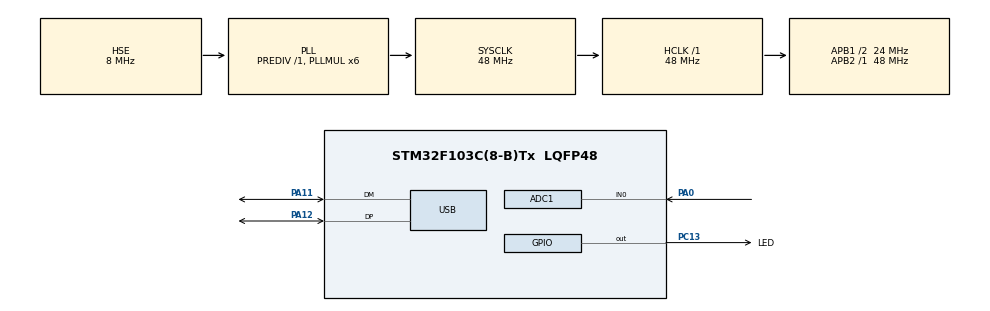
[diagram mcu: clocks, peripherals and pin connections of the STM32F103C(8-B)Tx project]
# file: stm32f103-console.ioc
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ADC1.Channel-0\#ChannelRegularConversion=ADC_CHANNEL_0
ADC1.ExternalTrigConv=ADC_SOFTWARE_START
ADC1.NbrOfConversionFlag=1
ADC1.Rank-0\#ChannelRegularConversion=1
ADC1.SamplingTime-0\#ChannelRegularConversion=ADC_SAMPLETIME_1CYCLE_5
ADC1.master=1
Dma.ADC1.0.Direction=DMA_PERIPH_TO_MEMORY
Dma.ADC1.0.Instance=DMA1_Channel1
Dma.ADC1.0.MemDataAlignment=DMA_MDATAALIGN_HALFWORD
Dma.ADC1.0.MemInc=DMA_MINC_ENABLE
Dma.ADC1.0.Mode=DMA_CIRCULAR
Dma.ADC1.0.PeriphDataAlignment=DMA_PDATAALIGN_HALFWORD
Dma.ADC1.0.PeriphInc=DMA_PINC_DISABLE
Dma.ADC1.0.Priority=DMA_PRIORITY_LOW
Dma.Request0=ADC1
FREERTOS.Tasks01=defaultTask,24,128,StartDefaultTask,Default,NULL,Dynamic,NULL,NULL
Mcu.Family=STM32F1
Mcu.Name=STM32F103C(8-B)Tx
Mcu.Package=LQFP48
NVIC.DMA1_Channel1_IRQn=true\:5\:0\:false\:false\:true\:true\:false\:true\:true
NVIC.PriorityGroup=NVIC_PRIORITYGROUP_4
NVIC.USB_LP_CAN1_RX0_IRQn=true\:5\:0\:false\:false\:true\:true\:false\:true\:true
PA0-WKUP.Signal=ADCx_IN0
PA11.Mode=Device
PA11.Signal=USB_DM
PA12.Mode=Device
PA12.Signal=USB_DP
PC13-TAMPER-RTC.GPIO_Label=LED
PC13-TAMPER-RTC.Signal=GPIO_Output
PD0-OSC_IN.Mode=HSE-External-Oscillator
PD0-OSC_IN.Signal=RCC_OSC_IN
PD1-OSC_OUT.Mode=HSE-External-Oscillator
PD1-OSC_OUT.Signal=RCC_OSC_OUT
ProjectManager.HeapSize=0x200
ProjectManager.StackSize=0x400
ProjectManager.TargetToolchain=STM32CubeIDE
RCC.ADCPresc=RCC_ADCPCLK2_DIV4
RCC.AHBFreq_Value=48000000
RCC.APB1CLKDivider=RCC_HCLK_DIV2
RCC.APB1Freq_Value=24000000
RCC.APB1TimFreq_Value=48000000
RCC.APB2Freq_Value=48000000
RCC.APB2TimFreq_Value=48000000
RCC.HCLKFreq_Value=48000000
RCC.PLLMUL=RCC_PLL_MUL6
RCC.SYSCLKFreq_VALUE=48000000
RCC.SYSCLKSource=RCC_SYSCLKSOURCE_PLLCLK
RCC.USBFreq_Value=48000000
SH.ADCx_IN0.0=ADC1_IN0,IN0
USB_DEVICE.CLASS_NAME_FS=CDC
USB_DEVICE.VirtualMode=Cdc
USB_DEVICE.VirtualModeFS=Cdc_FS
VP_FREERTOS_VS_CMSIS_V2.Mode=CMSIS_V2
VP_SYS_VS_ND.Mode=No_Debug
VP_TIM3_VS_ClockSourceINT.Mode=Internal
VP_USB_DEVICE_VS_USB_DEVICE_CDC_FS.Mode=CDC_FS
board=custom

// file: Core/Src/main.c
/* USER CODE BEGIN Header */
/**
  ******************************************************************************
  * @file           : main.c
  * @brief          : Main program body
  ******************************************************************************
  * @attention
  *
  * Copyright (c) 2025 STMicroelectronics.
  * All rights reserved.
  *
  * This software is licensed under terms that can be found in the LICENSE file
  * in the root directory of this software component.
  * If no LICENSE file comes with this software, it is provided AS-IS.
  *
  ******************************************************************************
  */
/* USER CODE END Header */
#include "main.h"
#include "cmsis_os.h"
#include "usb_device.h"
#include "shell.h"
#include "FreeRTOS.h"
#include "task.h"

ADC_HandleTypeDef hadc1;
DMA_HandleTypeDef hdma_adc1;

TIM_HandleTypeDef htim3;

volatile uint32_t g_boot_stage = 0U;
volatile uint32_t g_usb_stage = 0U;

/* Definitions for defaultTask */
osThreadId_t defaultTaskHandle;
static StaticTask_t defaultTaskControlBlock;
static StackType_t defaultTaskStack[128];
const osThreadAttr_t defaultTask_attributes = {
  .name = "defaultTask",
  .cb_mem = &defaultTaskControlBlock,
  .cb_size = sizeof(defaultTaskControlBlock),
  .stack_mem = defaultTaskStack,
  .stack_size = sizeof(defaultTaskStack),
  .priority = (osPriority_t) osPriorityNormal,
};

/* Shell task */
osThreadId_t shellTaskHandle;
static StaticTask_t shellTaskControlBlock;
static StackType_t shellTaskStack[256];
const osThreadAttr_t shellTask_attributes = {
  .name = "shellTask",
  .cb_mem = &shellTaskControlBlock,
  .cb_size = sizeof(shellTaskControlBlock),
  .stack_mem = shellTaskStack,
  .stack_size = sizeof(shellTaskStack),
  .priority = (osPriority_t) osPriorityNormal,
};

void SystemClock_Config(void);
static HAL_StatusTypeDef SystemClock_Config_HSI_Fallback(void);
static void LED_Output_Init(void);
static volatile LedMode led_mode = LED_MODE_BLINK;
static void MX_GPIO_Init(void);
static void MX_DMA_Init(void);
static void MX_ADC1_Init(void);
static void MX_TIM3_Init(void);
void StartDefaultTask(void *argument);

int main(void)
{

  /* MCU Configuration--------------------------------------------------------*/

  g_boot_stage = 1U;

  /* Reset of all peripherals, Initializes the Flash interface and the Systick. */
  HAL_Init();
  g_boot_stage = 2U;

  /* Make startup failures visible even if the external HSE is unavailable. */
  LED_Output_Init();

#ifndef STM32_DIAG_RTOS_ONLY
  /* Configure the system clock */
  SystemClock_Config();
  g_boot_stage = 3U;
#else
  /* Keep the diagnostic on the reset HSI clock.  This isolates the RTOS and
     GPIO path from HSE/PLL and all application peripherals. */
  g_boot_stage = 3U;
#endif

  /* Initialize all configured peripherals */
#ifndef STM32_DIAG_RTOS_ONLY
  MX_GPIO_Init();
  MX_DMA_Init();
  MX_ADC1_Init();
  MX_TIM3_Init();
#endif
  /* USER CODE BEGIN 2 */
#if !defined(STM32_DIAG_NO_USB) && !defined(STM32_DIAG_RTOS_ONLY)
  Shell_Init();
#endif
  /* PC13 is the physical Blue Pill LED.  Keep it owned by the heartbeat and
     prevent a persisted shell setting from leaving it as an input. */
  LED_Output_Init();
  /* Re-apply the persisted LED mode after the GPIO initialization default. */
  LED_SetMode(LED_GetMode());
  g_boot_stage = 4U;

  /* USER CODE END 2 */

  /* Init scheduler */
  osKernelInitialize();

  /* Create the thread(s) */
  /* creation of defaultTask */
  defaultTaskHandle = osThreadNew(StartDefaultTask, NULL, &defaultTask_attributes);

  shellTaskHandle = NULL;
#if !defined(STM32_DIAG_NO_USB) && !defined(STM32_DIAG_RTOS_ONLY)
  shellTaskHandle = osThreadNew(Shell_Task, NULL, &shellTask_attributes);
#endif
  if (defaultTaskHandle == NULL
#if !defined(STM32_DIAG_NO_USB) && !defined(STM32_DIAG_RTOS_ONLY)
      || shellTaskHandle == NULL
#endif
     )
  {
    Error_Handler();
  }
  g_boot_stage = 5U;

  /* Start scheduler */
  g_boot_stage = 6U;
  osKernelStart();

  /* We should never get here as control is now taken by the scheduler */

  /* Infinite loop */
  while (1)
  {

  }
}

void SystemClock_Config(void)
{
  RCC_OscInitTypeDef osc = {0};
  RCC_ClkInitTypeDef clk = {0};
  RCC_PeriphCLKInitTypeDef periph = {0};

  /* Blue Pill USB needs a stable external 8 MHz reference. */
  osc.OscillatorType = RCC_OSCILLATORTYPE_HSE;
  osc.HSEState = RCC_HSE_ON;
  osc.HSEPredivValue = RCC_HSE_PREDIV_DIV1;
  osc.HSIState = RCC_HSI_ON;
  osc.PLL.PLLState = RCC_PLL_ON;
  osc.PLL.PLLSource = RCC_PLLSOURCE_HSE;
  osc.PLL.PLLMUL = RCC_PLL_MUL6;

  if (HAL_RCC_OscConfig(&osc) == HAL_OK)
  {
    clk.ClockType = RCC_CLOCKTYPE_HCLK | RCC_CLOCKTYPE_SYSCLK |
                    RCC_CLOCKTYPE_PCLK1 | RCC_CLOCKTYPE_PCLK2;
    clk.SYSCLKSource = RCC_SYSCLKSOURCE_PLLCLK;
    clk.AHBCLKDivider = RCC_SYSCLK_DIV1;
    clk.APB1CLKDivider = RCC_HCLK_DIV2;
    clk.APB2CLKDivider = RCC_HCLK_DIV1;
    if (HAL_RCC_ClockConfig(&clk, FLASH_LATENCY_1) == HAL_OK)
    {
      periph.PeriphClockSelection = RCC_PERIPHCLK_ADC | RCC_PERIPHCLK_USB;
      periph.AdcClockSelection = RCC_ADCPCLK2_DIV4;
      periph.UsbClockSelection = RCC_USBCLKSOURCE_PLL;
      if (HAL_RCCEx_PeriphCLKConfig(&periph) == HAL_OK) return;
    }
  }

  /* Boards with a missing HSE can still run GPIO/RTOS from HSI. */
  if (SystemClock_Config_HSI_Fallback() != HAL_OK)
  {
    Error_Handler();
  }
}

static HAL_StatusTypeDef SystemClock_Config_HSI_Fallback(void)
{
  RCC_OscInitTypeDef osc = {0};
  RCC_ClkInitTypeDef clk = {0};
  RCC_PeriphCLKInitTypeDef periph = {0};

  osc.OscillatorType = RCC_OSCILLATORTYPE_HSI;
  osc.HSIState = RCC_HSI_ON;
  osc.HSICalibrationValue = RCC_HSICALIBRATION_DEFAULT;
  osc.PLL.PLLState = RCC_PLL_ON;
  osc.PLL.PLLSource = RCC_PLLSOURCE_HSI_DIV2;
  osc.PLL.PLLMUL = RCC_PLL_MUL12;
  if (HAL_RCC_OscConfig(&osc) != HAL_OK) return HAL_ERROR;

  clk.ClockType = RCC_CLOCKTYPE_HCLK | RCC_CLOCKTYPE_SYSCLK |
                  RCC_CLOCKTYPE_PCLK1 | RCC_CLOCKTYPE_PCLK2;
  clk.SYSCLKSource = RCC_SYSCLKSOURCE_PLLCLK;
  clk.AHBCLKDivider = RCC_SYSCLK_DIV1;
  clk.APB1CLKDivider = RCC_HCLK_DIV2;
  clk.APB2CLKDivider = RCC_HCLK_DIV1;
  if (HAL_RCC_ClockConfig(&clk, FLASH_LATENCY_1) != HAL_OK) return HAL_ERROR;

  periph.PeriphClockSelection = RCC_PERIPHCLK_ADC | RCC_PERIPHCLK_USB;
  periph.AdcClockSelection = RCC_ADCPCLK2_DIV4;
  periph.UsbClockSelection = RCC_USBCLKSOURCE_PLL;
  return HAL_RCCEx_PeriphCLKConfig(&periph);
}

static void LED_Output_Init(void)
{
  GPIO_InitTypeDef led = {0};

  __HAL_RCC_GPIOC_CLK_ENABLE();
  led.Pin = LED_Pin;
  led.Mode = GPIO_MODE_OUTPUT_PP;
  led.Pull = GPIO_NOPULL;
  led.Speed = GPIO_SPEED_FREQ_LOW;
  HAL_GPIO_Init(LED_GPIO_Port, &led);
  HAL_GPIO_WritePin(LED_GPIO_Port, LED_Pin, GPIO_PIN_SET);
}

void LED_SetMode(LedMode mode)
{
  led_mode = mode;
  if (mode == LED_MODE_ON) {
    HAL_GPIO_WritePin(LED_GPIO_Port, LED_Pin, GPIO_PIN_RESET);
  } else if (mode == LED_MODE_OFF) {
    HAL_GPIO_WritePin(LED_GPIO_Port, LED_Pin, GPIO_PIN_SET);
  }
}

LedMode LED_GetMode(void)
{
  return led_mode;
}

static void MX_ADC1_Init(void)
{

  ADC_ChannelConfTypeDef sConfig = {0};

  /** Common config
  */
  hadc1.Instance = ADC1;
  hadc1.Init.ScanConvMode = ADC_SCAN_DISABLE;
  hadc1.Init.ContinuousConvMode = DISABLE;
  hadc1.Init.DiscontinuousConvMode = DISABLE;
  hadc1.Init.ExternalTrigConv = ADC_SOFTWARE_START;
  hadc1.Init.DataAlign = ADC_DATAALIGN_RIGHT;
  hadc1.Init.NbrOfConversion = 1;
  if (HAL_ADC_Init(&hadc1) != HAL_OK)
  {
    Error_Handler();
  }

  /** Configure Regular Channel
  */
  sConfig.Channel = ADC_CHANNEL_0;
  sConfig.Rank = ADC_REGULAR_RANK_1;
  sConfig.SamplingTime = ADC_SAMPLETIME_1CYCLE_5;
  if (HAL_ADC_ConfigChannel(&hadc1, &sConfig) != HAL_OK)
  {
    Error_Handler();
  }

}

static void MX_TIM3_Init(void)
{

  TIM_ClockConfigTypeDef sClockSourceConfig = {0};
  TIM_MasterConfigTypeDef sMasterConfig = {0};

  htim3.Instance = TIM3;
  htim3.Init.Prescaler = 0;
  htim3.Init.CounterMode = TIM_COUNTERMODE_UP;
  htim3.Init.Period = 65535;
  htim3.Init.ClockDivision = TIM_CLOCKDIVISION_DIV1;
  htim3.Init.AutoReloadPreload = TIM_AUTORELOAD_PRELOAD_DISABLE;
  if (HAL_TIM_Base_Init(&htim3) != HAL_OK)
  {
    Error_Handler();
  }
  sClockSourceConfig.ClockSource = TIM_CLOCKSOURCE_INTERNAL;
  if (HAL_TIM_ConfigClockSource(&htim3, &sClockSourceConfig) != HAL_OK)
  {
    Error_Handler();
  }
  sMasterConfig.MasterOutputTrigger = TIM_TRGO_UPDATE;
  sMasterConfig.MasterSlaveMode = TIM_MASTERSLAVEMODE_DISABLE;
  if (HAL_TIMEx_MasterConfigSynchronization(&htim3, &sMasterConfig) != HAL_OK)
  {
    Error_Handler();
  }

}

static void MX_DMA_Init(void)
{

  /* DMA controller clock enable */
  __HAL_RCC_DMA1_CLK_ENABLE();

  /* DMA interrupt init */
  /* DMA1_Channel1_IRQn interrupt configuration */
  HAL_NVIC_SetPriority(DMA1_Channel1_IRQn, 5, 0);
  HAL_NVIC_EnableIRQ(DMA1_Channel1_IRQn);

}

static void MX_GPIO_Init(void)
{
  GPIO_InitTypeDef GPIO_InitStruct = {0};

  /* GPIO Ports Clock Enable */
  __HAL_RCC_GPIOC_CLK_ENABLE();
  __HAL_RCC_GPIOD_CLK_ENABLE();
  __HAL_RCC_GPIOA_CLK_ENABLE();
  __HAL_RCC_GPIOB_CLK_ENABLE();

  /*Configure GPIO pin Output Level */
  HAL_GPIO_WritePin(LED_GPIO_Port, LED_Pin, GPIO_PIN_SET);

  /*Configure GPIO pin : LED_Pin */
  GPIO_InitStruct.Pin = LED_Pin;
  GPIO_InitStruct.Mode = GPIO_MODE_OUTPUT_PP;
  GPIO_InitStruct.Pull = GPIO_NOPULL;
  GPIO_InitStruct.Speed = GPIO_SPEED_FREQ_LOW;
  HAL_GPIO_Init(LED_GPIO_Port, &GPIO_InitStruct);

}

void StartDefaultTask(void *argument)
{
  (void)argument;

  /* Keep the first validation path deliberately boring: one FreeRTOS task,
     one HAL GPIO, and one delay.  This isolates RTOS/GPIO/clock issues from
     USB CDC, shell, DMA, and timer interrupt configuration. */
  g_boot_stage = 7U;
  for(;;)
  {
    LedMode mode = LED_GetMode();
    if (mode == LED_MODE_BLINK) {
      HAL_GPIO_TogglePin(LED_GPIO_Port, LED_Pin);
      osDelay(500);
    } else {
      LED_SetMode(mode);
      osDelay(100);
    }
  }
}

void Error_Handler(void)
{
  /* USER CODE BEGIN Error_Handler_Debug */
  /* User can add his own implementation to report the HAL error return state */
  __disable_irq();
  while (1)
  {
    HAL_GPIO_TogglePin(LED_GPIO_Port, LED_Pin);
    for (volatile uint32_t delay = 0; delay < 500000U; ++delay) { }
  }
  /* USER CODE END Error_Handler_Debug */
}
